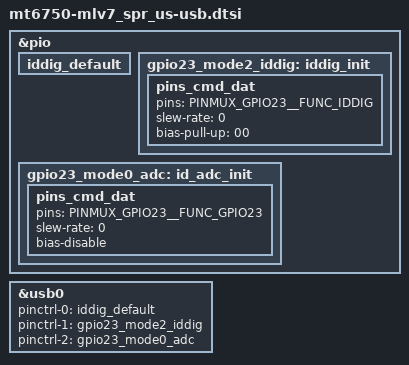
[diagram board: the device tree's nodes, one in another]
/*
 * LG Electronics LS7 usb device tree source
 *
 * Copyright (c) 2017 LG Electronics Co., Ltd.
 *              http://www.lge.com
 *
 */

&pio {
	iddig_default: iddig_default {
	};

	gpio23_mode2_iddig: iddig_init {
		pins_cmd_dat {
			pins = <PINMUX_GPIO23__FUNC_IDDIG>;
			slew-rate = <0>;
			bias-pull-up = <00>;
		};
	};

	gpio23_mode0_adc: id_adc_init {
		pins_cmd_dat {
			pins = <PINMUX_GPIO23__FUNC_GPIO23>;
			slew-rate = <0>;
			bias-disable;
		};
	};
};

&usb0 {
	pinctrl-names = "iddig_default", "iddig_init", "id_adc_init";
	pinctrl-0 = <&iddig_default>;
	pinctrl-1 = <&gpio23_mode2_iddig>;
	pinctrl-2 = <&gpio23_mode0_adc>;
	status = "okay";
};

